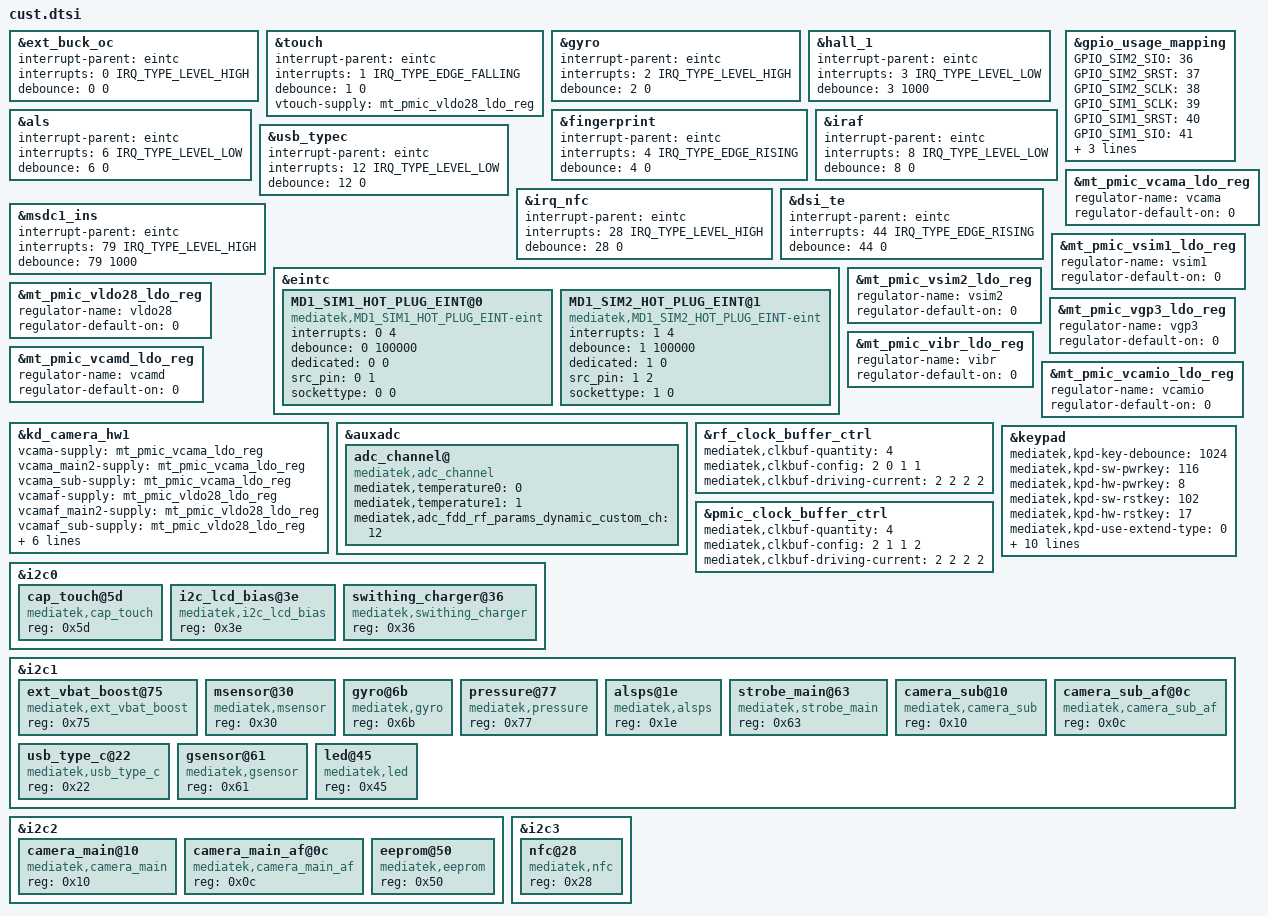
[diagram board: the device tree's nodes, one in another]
/*
 * Generated by MTK SP Drv_CodeGen Version 03.13.6  for MT6755. Copyright MediaTek Inc. (C) 2013.
 * Wed Jul  6 14:06:08 2016
 * Do Not Modify the File.
 */

#include <dt-bindings/interrupt-controller/irq.h>
#include <dt-bindings/interrupt-controller/arm-gic.h>

/*************************
 * EINT DTSI File
*************************/

&ext_buck_oc {
	interrupt-parent = <&eintc>;
	interrupts = <0 IRQ_TYPE_LEVEL_HIGH>;
	debounce = <0 0>;
	status = "okay";
};
&touch {
	interrupt-parent = <&eintc>;
	interrupts = <1 IRQ_TYPE_EDGE_FALLING>;
	debounce = <1 0>;
	status = "okay";
};
&gyro {
	interrupt-parent = <&eintc>;
	interrupts = <2 IRQ_TYPE_LEVEL_HIGH>;
	debounce = <2 0>;
	status = "okay";
};
&hall_1 {
	interrupt-parent = <&eintc>;
	interrupts = <3 IRQ_TYPE_LEVEL_LOW>;
	debounce = <3 1000>;
	status = "okay";
};
&fingerprint {
	interrupt-parent = <&eintc>;
	interrupts = <4 IRQ_TYPE_EDGE_RISING>;
	debounce = <4 0>;
	status = "okay";
};
&als {
	interrupt-parent = <&eintc>;
	interrupts = <6 IRQ_TYPE_LEVEL_LOW>;
	debounce = <6 0>;
	status = "okay";
};
&iraf {
	interrupt-parent = <&eintc>;
	interrupts = <8 IRQ_TYPE_LEVEL_LOW>;
	debounce = <8 0>;
	status = "okay";
};
&usb_typec {
	interrupt-parent = <&eintc>;
	interrupts = <12 IRQ_TYPE_LEVEL_LOW>;
	debounce = <12 0>;
	status = "okay";
};
&irq_nfc {
	interrupt-parent = <&eintc>;
	interrupts = <28 IRQ_TYPE_LEVEL_HIGH>;
	debounce = <28 0>;
	status = "okay";
};
&dsi_te {
	interrupt-parent = <&eintc>;
	interrupts = <44 IRQ_TYPE_EDGE_RISING>;
	debounce = <44 0>;
	status = "okay";
};
&msdc1_ins {
	interrupt-parent = <&eintc>;
	interrupts = <79 IRQ_TYPE_LEVEL_HIGH>;
	debounce = <79 1000>;
	status = "okay";
};


/********************
 * GPIO USAGE MAPPING DTSI File
****************/

&gpio_usage_mapping {
	GPIO_SIM2_SIO = <36>;
	GPIO_SIM2_SRST = <37>;
	GPIO_SIM2_SCLK = <38>;
	GPIO_SIM1_SCLK = <39>;
	GPIO_SIM1_SRST = <40>;
	GPIO_SIM1_SIO = <41>;
	GPIO_FDD_BAND_SUPPORT_DETECT_1ST_PIN = <80>;
	GPIO_FDD_BAND_SUPPORT_DETECT_2ND_PIN = <81>;
	GPIO_FDD_BAND_SUPPORT_DETECT_3RD_PIN = <82>;
};


&eintc {
	MD1_SIM1_HOT_PLUG_EINT@0 {
		compatible = "mediatek,MD1_SIM1_HOT_PLUG_EINT-eint";
		interrupts = <0 4>;
		debounce = <0 100000>;
		dedicated = <0 0>;
		src_pin = <0 1>;
		sockettype=<0 0>;
		status = "okay";
	};
	MD1_SIM2_HOT_PLUG_EINT@1 {
		compatible = "mediatek,MD1_SIM2_HOT_PLUG_EINT-eint";
		interrupts = <1 4>;
		debounce = <1 100000>;
		dedicated = <1 0>;
		src_pin = <1 2>;
		sockettype=<1 0>;
		status = "okay";
	};
};


/*************************
 * PMIC DTSI File
*************************/

&mt_pmic_vcama_ldo_reg {
	regulator-name = "vcama";
	regulator-default-on = <0>; /* 0:skip, 1: off, 2:on */
	status = "okay";
};
&mt_pmic_vsim1_ldo_reg {
	regulator-name = "vsim1";
	regulator-default-on = <0>; /* 0:skip, 1: off, 2:on */
	status = "okay";
};
&mt_pmic_vsim2_ldo_reg {
	regulator-name = "vsim2";
	regulator-default-on = <0>; /* 0:skip, 1: off, 2:on */
	status = "okay";
};
&mt_pmic_vldo28_ldo_reg {
	regulator-name = "vldo28";
	regulator-default-on = <0>; /* 0:skip, 1: off, 2:on */
	status = "okay";
};
&mt_pmic_vgp3_ldo_reg {
	regulator-name = "vgp3";
	regulator-default-on = <0>; /* 0:skip, 1: off, 2:on */
	status = "okay";
};
&mt_pmic_vibr_ldo_reg {
	regulator-name = "vibr";
	regulator-default-on = <0>; /* 0:skip, 1: off, 2:on */
	status = "okay";
};
&mt_pmic_vcamd_ldo_reg {
	regulator-name = "vcamd";
	regulator-default-on = <0>; /* 0:skip, 1: off, 2:on */
	status = "okay";
};
&mt_pmic_vcamio_ldo_reg {
	regulator-name = "vcamio";
	regulator-default-on = <0>; /* 0:skip, 1: off, 2:on */
	status = "okay";
};

&kd_camera_hw1 {
	vcama-supply = <&mt_pmic_vcama_ldo_reg>;
	vcama_main2-supply = <&mt_pmic_vcama_ldo_reg>;
	vcama_sub-supply = <&mt_pmic_vcama_ldo_reg>;

	vcamaf-supply = <&mt_pmic_vldo28_ldo_reg>;
	vcamaf_main2-supply = <&mt_pmic_vldo28_ldo_reg>;
	vcamaf_sub-supply = <&mt_pmic_vldo28_ldo_reg>;

	vcamd_main2-supply = <&mt_pmic_vgp3_ldo_reg>;
	vcamd_sub-supply = <&mt_pmic_vgp3_ldo_reg>;

	vcamd-supply = <&mt_pmic_vcamd_ldo_reg>;

	vcamio-supply = <&mt_pmic_vcamio_ldo_reg>;
	vcamio_main2-supply = <&mt_pmic_vcamio_ldo_reg>;
	vcamio_sub-supply = <&mt_pmic_vcamio_ldo_reg>;

	status = "okay";
};

&touch {
	vtouch-supply = <&mt_pmic_vldo28_ldo_reg>;
	status = "okay";
};


/********************************************
 *ADC DTSI File
********************************************/

&auxadc {
	adc_channel@ {
		compatible = "mediatek,adc_channel";
		mediatek,temperature0 = <0>;
		mediatek,temperature1 = <1>;
		mediatek,adc_fdd_rf_params_dynamic_custom_ch = <12>;
		status = "okay";
	};
};


/**********************************************
 *CLK_BUF DTSI File
********************************************/

&rf_clock_buffer_ctrl {
	mediatek,clkbuf-quantity = <4>;
	mediatek,clkbuf-config = <2 0 1 1>;
	mediatek,clkbuf-driving-current = <2 2 2 2>;
	status = "okay";
};

&pmic_clock_buffer_ctrl {
	mediatek,clkbuf-quantity = <4>;
	mediatek,clkbuf-config = <2 1 1 2>;
	mediatek,clkbuf-driving-current = <2 2 2 2>;
	status = "okay";
};


/**********************************************
 *Keypad DTSI File
********************************************/

&keypad{
	mediatek,kpd-key-debounce = <1024>;
	mediatek,kpd-sw-pwrkey = <116>;
	mediatek,kpd-hw-pwrkey = <8>;
	mediatek,kpd-sw-rstkey  = <102>;
	mediatek,kpd-hw-rstkey = <17>;
	mediatek,kpd-use-extend-type = <0>;
	/*HW Keycode [0~71] -> Linux Keycode*/
	mediatek,kpd-hw-map-num = <72>;
	mediatek,kpd-hw-init-map = <0 250 0 0 0 0 0 0 0 115 114 0 0 0 0 0 0 0 0 0 0 0 0 0 0 0 0 0 0 0 0 0 0 0 0 0 0 0 0 0 0 0 0 0 0 0 0 0 0 0 0 0 0 0 0 0 0 0 0 102 0 0 0 0 0 0 0 0 0 0 0 0>;
	mediatek,kpd-pwrkey-eint-gpio = <0>;
	mediatek,kpd-pwkey-gpio-din  = <0>;
	mediatek,kpd-hw-dl-key0 = <9>;
	mediatek,kpd-hw-dl-key1 = <10>;
	mediatek,kpd-hw-dl-key2 = <8>;
	mediatek,kpd-hw-recovery-key = <9>;
	mediatek,kpd-hw-factory-key = <10>;
	status = "okay";
};


/*************************
 * I2C DTSI File
*************************/

&i2c0 {
	#address-cells = <1>;
	#size-cells = <0>;
	cap_touch@5d {
		compatible = "mediatek,cap_touch";
		reg = <0x5d>;
		status = "okay";
	};
	i2c_lcd_bias@3e {
		compatible = "mediatek,i2c_lcd_bias";
		reg = <0x3e>;
		status = "okay";
	};
	swithing_charger@36 {
		compatible = "mediatek,swithing_charger";
		reg = <0x36>;
		status = "okay";
	};
};

&i2c1 {
	#address-cells = <1>;
	#size-cells = <0>;
	ext_vbat_boost@75 {
		compatible = "mediatek,ext_vbat_boost";
		reg = <0x75>;
		status = "okay";
	};
	msensor@30 {
		compatible = "mediatek,msensor";
		reg = <0x30>;
		status = "okay";
	};
	gyro@6b {
		compatible = "mediatek,gyro";
		reg = <0x6b>;
		status = "okay";
	};
	pressure@77 {
		compatible = "mediatek,pressure";
		reg = <0x77>;
		status = "okay";
	};
	alsps@1e {
		compatible = "mediatek,alsps";
		reg = <0x1e>;
		status = "okay";
	};
	strobe_main@63 {
		compatible = "mediatek,strobe_main";
		reg = <0x63>;
		status = "okay";
	};
	camera_sub@10 {
		compatible = "mediatek,camera_sub";
		reg = <0x10>;
		status = "okay";
	};
	camera_sub_af@0c {
		compatible = "mediatek,camera_sub_af";
		reg = <0x0c>;
		status = "okay";
	};
	usb_type_c@22 {
		compatible = "mediatek,usb_type_c";
		reg = <0x22>;
		status = "okay";
	};
	gsensor@61 {
		compatible = "mediatek,gsensor";
		reg = <0x61>;
		status = "okay";
	};
	led@45 {
		compatible = "mediatek,led";
		reg = <0x45>;
		status = "okay";
	};
};

&i2c2 {
	#address-cells = <1>;
	#size-cells = <0>;
	camera_main@10 {
		compatible = "mediatek,camera_main";
		reg = <0x10>;
		status = "okay";
	};
	camera_main_af@0c {
		compatible = "mediatek,camera_main_af";
		reg = <0x0c>;
		status = "okay";
	};
	eeprom@50 {
		compatible = "mediatek,eeprom";
		reg = <0x50>;
		status = "okay";
	};
};

&i2c3 {
	#address-cells = <1>;
	#size-cells = <0>;
	nfc@28 {
		compatible = "mediatek,nfc";
		reg = <0x28>;
		status = "okay";
	};
};



